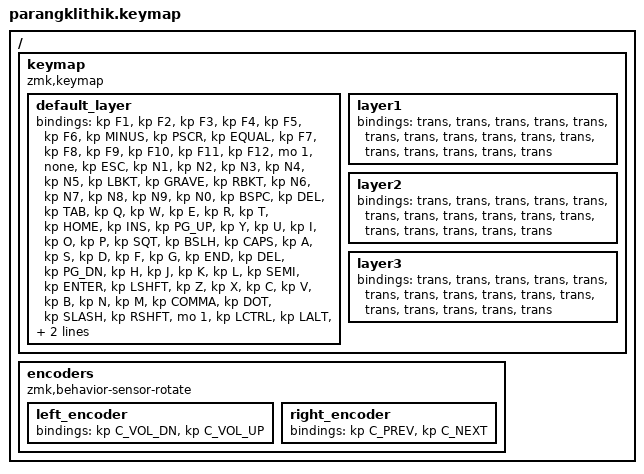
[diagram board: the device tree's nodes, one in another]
// This file was generated from a template. Edit it to match your keyboard.
// See https://zmk.dev/docs/development/hardware-integration/new-shield for more instructions.

#include <behaviors.dtsi>
#include <dt-bindings/zmk/keys.h>

/ {
    keymap {
        compatible = "zmk,keymap";

        default_layer {

            bindings = <
&kp F1  &kp F2  &kp F3  &kp F4  &kp F5  &kp F6   &kp MINUS &kp PSCR &kp EQUAL  &kp F7  &kp F8  &kp F9  &kp F10 &kp F11 &kp F12 &mo 1 &none

&kp ESC  &kp N1 &kp N2 &kp N3 &kp N4 &kp N5  &kp LBKT &kp GRAVE &kp RBKT &kp N6 &kp N7 &kp N8 &kp N9 &kp N0 &kp BSPC &kp DEL

&kp TAB  &kp Q &kp W &kp E &kp R &kp T   &kp HOME &kp INS &kp PG_UP &kp Y &kp U &kp I &kp O &kp P &kp SQT &kp BSLH

&kp CAPS &kp A &kp S &kp D &kp F &kp G   &kp END &kp DEL &kp PG_DN &kp H &kp J &kp K &kp L &kp SEMI &kp ENTER

&kp LSHFT &kp Z &kp X &kp C &kp V &kp B   &kp N &kp M &kp COMMA &kp DOT &kp SLASH &kp RSHFT

&mo 1 &kp LCTRL &kp LALT &kp LGUI &kp SPACE &kp SPACE &kp DEL &kp RCTRL &kp RGUI &mo 2
            >;
        };

        layer1 {
            bindings = <
&trans &trans &trans &trans &trans &trans &trans &trans &trans &trans &trans &trans &trans &trans &trans &trans
            >;
        };

        layer2 {
            bindings = <
&trans &trans &trans &trans &trans &trans &trans &trans &trans &trans &trans &trans &trans &trans &trans &trans
            >;
        };

        layer3 {
            bindings = <
&trans &trans &trans &trans &trans &trans &trans &trans &trans &trans &trans &trans &trans &trans &trans &trans
            >;
        };
    };

    encoders {
        compatible = "zmk,behavior-sensor-rotate";

        left_encoder {
            bindings = <
                &kp C_VOL_DN
                &kp C_VOL_UP
            >;
        };

        right_encoder {
            bindings = <
                &kp C_PREV
                &kp C_NEXT
            >;
        };
    };
};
